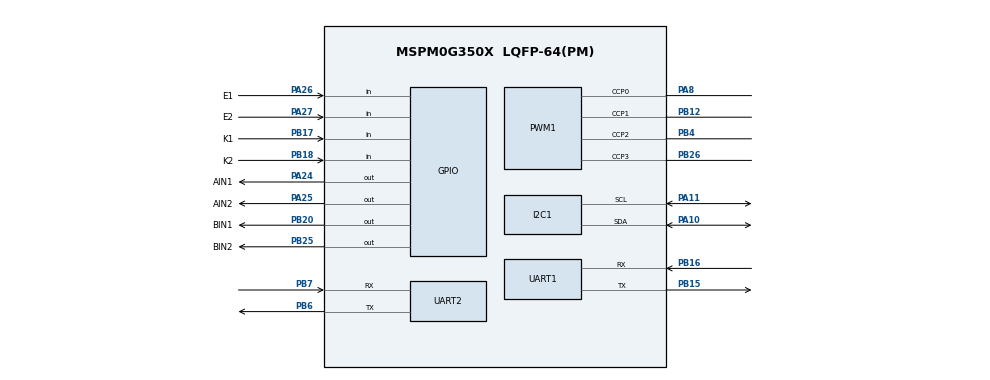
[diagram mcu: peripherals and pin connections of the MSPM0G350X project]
/**
 * @cliArgs --device "MSPM0G350X" --part "Default" --package "LQFP-64(PM)" --product "mspm0_sdk@2.11.00.07"
 * @versions {"tool":"1.26.2+4477"}
 */

/**
 * Import the modules used in this configuration.
 */
const GPIO   = scripting.addModule("/ti/driverlib/GPIO", {}, false);
const GPIO1  = GPIO.addInstance();
const GPIO2  = GPIO.addInstance();
const GPIO3  = GPIO.addInstance();
const GPIO4  = GPIO.addInstance();
const GPIO5  = GPIO.addInstance();
const GPIO6  = GPIO.addInstance();
const I2C    = scripting.addModule("/ti/driverlib/I2C", {}, false);
const I2C1   = I2C.addInstance();
const PWM    = scripting.addModule("/ti/driverlib/PWM", {}, false);
const PWM1   = PWM.addInstance();
const SYSCTL = scripting.addModule("/ti/driverlib/SYSCTL");
const TIMER  = scripting.addModule("/ti/driverlib/TIMER", {}, false);
const TIMER1 = TIMER.addInstance();
const TIMER2 = TIMER.addInstance();
const UART   = scripting.addModule("/ti/driverlib/UART", {}, false);
const UART1  = UART.addInstance();
const UART2  = UART.addInstance();

/**
 * Write custom configuration values to the imported modules.
 */
const divider9       = system.clockTree["UDIV"];
divider9.divideValue = 2;

const multiplier2         = system.clockTree["PLL_QDIV"];
multiplier2.multiplyValue = 5;

const mux8       = system.clockTree["HSCLKMUX"];
mux8.inputSelect = "HSCLKMUX_SYSPLL0";

GPIO1.$name                         = "AIN";
GPIO1.port                          = "PORTA";
GPIO1.associatedPins.create(2);
GPIO1.associatedPins[0].$name       = "AIN1";
GPIO1.associatedPins[0].ioStructure = "SD";
GPIO1.associatedPins[0].assignedPin = "24";
GPIO1.associatedPins[0].pin.$assign = "PA24";
GPIO1.associatedPins[1].$name       = "AIN2";
GPIO1.associatedPins[1].ioStructure = "SD";
GPIO1.associatedPins[1].assignedPin = "25";
GPIO1.associatedPins[1].pin.$assign = "PA25";

const Board = scripting.addModule("/ti/driverlib/Board", {}, false);

GPIO2.$name                         = "BIN";
GPIO2.port                          = "PORTB";
GPIO2.associatedPins.create(2);
GPIO2.associatedPins[0].$name       = "BIN1";
GPIO2.associatedPins[0].ioStructure = "SD";
GPIO2.associatedPins[0].assignedPin = "20";
GPIO2.associatedPins[0].pin.$assign = "PB20";
GPIO2.associatedPins[1].$name       = "BIN2";
GPIO2.associatedPins[1].ioStructure = "SD";
GPIO2.associatedPins[1].assignedPin = "25";
GPIO2.associatedPins[1].pin.$assign = "PB25";

GPIO3.$name                               = "Encoders";
GPIO3.port                                = "PORTA";
GPIO3.associatedPins.create(2);
GPIO3.associatedPins[0].$name             = "E1";
GPIO3.associatedPins[0].direction         = "INPUT";
GPIO3.associatedPins[0].interruptEn       = true;
GPIO3.associatedPins[0].interruptPriority = "0";
GPIO3.associatedPins[0].polarity          = "RISE";
GPIO3.associatedPins[0].assignedPin       = "26";
GPIO3.associatedPins[0].pin.$assign       = "PA26";
GPIO3.associatedPins[1].$name             = "E2";
GPIO3.associatedPins[1].direction         = "INPUT";
GPIO3.associatedPins[1].interruptEn       = true;
GPIO3.associatedPins[1].interruptPriority = "0";
GPIO3.associatedPins[1].polarity          = "RISE";
GPIO3.associatedPins[1].assignedPin       = "27";
GPIO3.associatedPins[1].pin.$assign       = "PA27";

GPIO4.$name                                 = "Pathfinding";
GPIO4.associatedPins.create(7);
GPIO4.associatedPins[0].$name               = "L3";
GPIO4.associatedPins[0].direction           = "INPUT";
GPIO4.associatedPins[0].assignedPort        = "PORTA";
GPIO4.associatedPins[0].assignedPortSegment = "Upper";
GPIO4.associatedPins[0].assignedPin         = "30";
GPIO4.associatedPins[0].internalResistor    = "PULL_UP";
GPIO4.associatedPins[1].$name               = "L2";
GPIO4.associatedPins[1].direction           = "INPUT";
GPIO4.associatedPins[1].assignedPort        = "PORTB";
GPIO4.associatedPins[1].assignedPin         = "1";
GPIO4.associatedPins[1].internalResistor    = "PULL_UP";
GPIO4.associatedPins[2].$name               = "L1";
GPIO4.associatedPins[2].direction           = "INPUT";
GPIO4.associatedPins[2].assignedPort        = "PORTB";
GPIO4.associatedPins[2].assignedPin         = "0";
GPIO4.associatedPins[2].internalResistor    = "PULL_UP";
GPIO4.associatedPins[3].$name               = "MC";
GPIO4.associatedPins[3].direction           = "INPUT";
GPIO4.associatedPins[3].assignedPort        = "PORTA";
GPIO4.associatedPins[3].assignedPin         = "7";
GPIO4.associatedPins[3].internalResistor    = "PULL_UP";
GPIO4.associatedPins[4].$name               = "R1";
GPIO4.associatedPins[4].direction           = "INPUT";
GPIO4.associatedPins[4].assignedPort        = "PORTB";
GPIO4.associatedPins[4].assignedPin         = "10";
GPIO4.associatedPins[4].internalResistor    = "PULL_UP";
GPIO4.associatedPins[5].$name               = "R2";
GPIO4.associatedPins[5].direction           = "INPUT";
GPIO4.associatedPins[5].assignedPort        = "PORTB";
GPIO4.associatedPins[5].assignedPin         = "14";
GPIO4.associatedPins[5].internalResistor    = "PULL_UP";
GPIO4.associatedPins[6].$name               = "R3";
GPIO4.associatedPins[6].direction           = "INPUT";
GPIO4.associatedPins[6].assignedPort        = "PORTB";
GPIO4.associatedPins[6].assignedPin         = "11";
GPIO4.associatedPins[6].internalResistor    = "PULL_UP";

GPIO5.$name                               = "key";
GPIO5.associatedPins.create(2);
GPIO5.associatedPins[0].$name             = "K1";
GPIO5.associatedPins[0].assignedPort      = "PORTB";
GPIO5.associatedPins[0].assignedPin       = "17";
GPIO5.associatedPins[0].direction         = "INPUT";
GPIO5.associatedPins[0].interruptEn       = true;
GPIO5.associatedPins[0].interruptPriority = "2";
GPIO5.associatedPins[0].polarity          = "RISE";
GPIO5.associatedPins[0].pin.$assign       = "PB17";
GPIO5.associatedPins[1].$name             = "K2";
GPIO5.associatedPins[1].direction         = "INPUT";
GPIO5.associatedPins[1].assignedPort      = "PORTB";
GPIO5.associatedPins[1].assignedPin       = "18";
GPIO5.associatedPins[1].interruptEn       = true;
GPIO5.associatedPins[1].interruptPriority = "2";
GPIO5.associatedPins[1].polarity          = "RISE";
GPIO5.associatedPins[1].pin.$assign       = "PB18";

GPIO6.$name                          = "HC05";
GPIO6.associatedPins[0].$name        = "STATE";
GPIO6.associatedPins[0].direction    = "INPUT";
GPIO6.associatedPins[0].assignedPort = "PORTB";
GPIO6.associatedPins[0].assignedPin  = "23";

I2C1.$name                             = "OLED";
I2C1.basicEnableController             = true;
I2C1.basicControllerStandardBusSpeed   = "Fast";
I2C1.advControllerClkStretch           = false;
I2C1.peripheral.$assign                = "I2C0";
I2C1.peripheral.sdaPin.$assign         = "PA10";
I2C1.peripheral.sclPin.$assign         = "PA11";
I2C1.sdaPinConfig.hideOutputInversion  = scripting.forceWrite(false);
I2C1.sdaPinConfig.onlyInternalResistor = scripting.forceWrite(false);
I2C1.sdaPinConfig.passedPeripheralType = scripting.forceWrite("Digital");
I2C1.sdaPinConfig.$name                = "ti_driverlib_gpio_GPIOPinGeneric4";
I2C1.sdaPinConfig.enableConfig         = true;
I2C1.sclPinConfig.hideOutputInversion  = scripting.forceWrite(false);
I2C1.sclPinConfig.onlyInternalResistor = scripting.forceWrite(false);
I2C1.sclPinConfig.passedPeripheralType = scripting.forceWrite("Digital");
I2C1.sclPinConfig.$name                = "ti_driverlib_gpio_GPIOPinGeneric5";
I2C1.sclPinConfig.enableConfig         = true;

PWM1.$name                      = "PWM_0";
PWM1.timerStartTimer            = true;
PWM1.ccIndex                    = [0,1,2,3];
PWM1.clockPrescale              = 5;
PWM1.PWM_CHANNEL_0.$name        = "ti_driverlib_pwm_PWMTimerCC0";
PWM1.PWM_CHANNEL_0.invert       = true;
PWM1.PWM_CHANNEL_1.$name        = "ti_driverlib_pwm_PWMTimerCC1";
PWM1.PWM_CHANNEL_1.invert       = true;
PWM1.ccp0PinConfig.$name        = "ti_driverlib_gpio_GPIOPinGeneric0";
PWM1.ccp1PinConfig.$name        = "ti_driverlib_gpio_GPIOPinGeneric1";
PWM1.peripheral.ccp0Pin.$assign = "PA8";
PWM1.peripheral.ccp1Pin.$assign = "PB12";
PWM1.peripheral.ccp2Pin.$assign = "PB4";
PWM1.peripheral.ccp3Pin.$assign = "PB26";
PWM1.PWM_CHANNEL_2.$name        = "ti_driverlib_pwm_PWMTimerCC2";
PWM1.PWM_CHANNEL_2.invert       = true;
PWM1.PWM_CHANNEL_3.$name        = "ti_driverlib_pwm_PWMTimerCC3";
PWM1.PWM_CHANNEL_3.invert       = true;
PWM1.ccp2PinConfig.$name        = "ti_driverlib_gpio_GPIOPinGeneric2";
PWM1.ccp3PinConfig.$name        = "ti_driverlib_gpio_GPIOPinGeneric3";

SYSCTL.forceDefaultClkConfig = true;
SYSCTL.clockTreeEn           = true;

TIMER1.$name              = "PID_TIM";
TIMER1.timerClkDiv        = 8;
TIMER1.timerClkPrescale   = 100;
TIMER1.timerPeriod        = "20ms";
TIMER1.timerStartTimer    = true;
TIMER1.timerMode          = "PERIODIC";
TIMER1.interrupts         = ["ZERO"];
TIMER1.interruptPriority  = "0";
TIMER1.peripheral.$assign = "TIMG0";

TIMER2.timerClkDiv       = 8;
TIMER2.timerClkPrescale  = 100;
TIMER2.timerMode         = "PERIODIC";
TIMER2.timerPeriod       = "40 ms";
TIMER2.timerStartTimer   = true;
TIMER2.$name             = "Pathfinding_TIM";
TIMER2.interrupts        = ["ZERO"];
TIMER2.interruptPriority = "1";

UART1.$name                            = "Gyro";
UART1.targetBaudRate                   = 115200;
UART1.rxFifoThreshold                  = "DL_UART_RX_FIFO_LEVEL_ONE_ENTRY";
UART1.enableDMARX                      = false;
UART1.enableDMATX                      = false;
UART1.enabledInterrupts                = ["RX"];
UART1.interruptPriority                = "1";
UART1.peripheral.$assign               = "UART2";
UART1.peripheral.rxPin.$assign         = "PB16";
UART1.peripheral.txPin.$assign         = "PB15";
UART1.txPinConfig.direction            = scripting.forceWrite("OUTPUT");
UART1.txPinConfig.hideOutputInversion  = scripting.forceWrite(false);
UART1.txPinConfig.onlyInternalResistor = scripting.forceWrite(false);
UART1.txPinConfig.passedPeripheralType = scripting.forceWrite("Digital");
UART1.txPinConfig.$name                = "ti_driverlib_gpio_GPIOPinGeneric6";
UART1.rxPinConfig.hideOutputInversion  = scripting.forceWrite(false);
UART1.rxPinConfig.onlyInternalResistor = scripting.forceWrite(false);
UART1.rxPinConfig.passedPeripheralType = scripting.forceWrite("Digital");
UART1.rxPinConfig.$name                = "ti_driverlib_gpio_GPIOPinGeneric7";

UART2.$name                            = "HC";
UART2.targetBaudRate                   = 115200;
UART2.enabledInterrupts                = ["RX"];
UART2.interruptPriority                = "2";
UART2.peripheral.$assign               = "UART1";
UART2.peripheral.rxPin.$assign         = "PB7";
UART2.peripheral.txPin.$assign         = "PB6";
UART2.txPinConfig.direction            = scripting.forceWrite("OUTPUT");
UART2.txPinConfig.hideOutputInversion  = scripting.forceWrite(false);
UART2.txPinConfig.onlyInternalResistor = scripting.forceWrite(false);
UART2.txPinConfig.passedPeripheralType = scripting.forceWrite("Digital");
UART2.txPinConfig.$name                = "ti_driverlib_gpio_GPIOPinGeneric8";
UART2.rxPinConfig.hideOutputInversion  = scripting.forceWrite(false);
UART2.rxPinConfig.onlyInternalResistor = scripting.forceWrite(false);
UART2.rxPinConfig.passedPeripheralType = scripting.forceWrite("Digital");
UART2.rxPinConfig.$name                = "ti_driverlib_gpio_GPIOPinGeneric9";

/**
 * Pinmux solution for unlocked pins/peripherals. This ensures that minor changes to the automatic solver in a future
 * version of the tool will not impact the pinmux you originally saw.  These lines can be completely deleted in order to
 * re-solve from scratch.
 */
Board.peripheral.$suggestSolution            = "DEBUGSS";
Board.peripheral.swclkPin.$suggestSolution   = "PA20";
Board.peripheral.swdioPin.$suggestSolution   = "PA19";
GPIO4.associatedPins[0].pin.$suggestSolution = "PA30";
GPIO4.associatedPins[1].pin.$suggestSolution = "PB1";
GPIO4.associatedPins[2].pin.$suggestSolution = "PB0";
GPIO4.associatedPins[3].pin.$suggestSolution = "PA7";
GPIO4.associatedPins[4].pin.$suggestSolution = "PB10";
GPIO4.associatedPins[5].pin.$suggestSolution = "PB14";
GPIO4.associatedPins[6].pin.$suggestSolution = "PB11";
GPIO6.associatedPins[0].pin.$suggestSolution = "PB23";
PWM1.peripheral.$suggestSolution             = "TIMA0";
TIMER2.peripheral.$suggestSolution           = "TIMA1";
